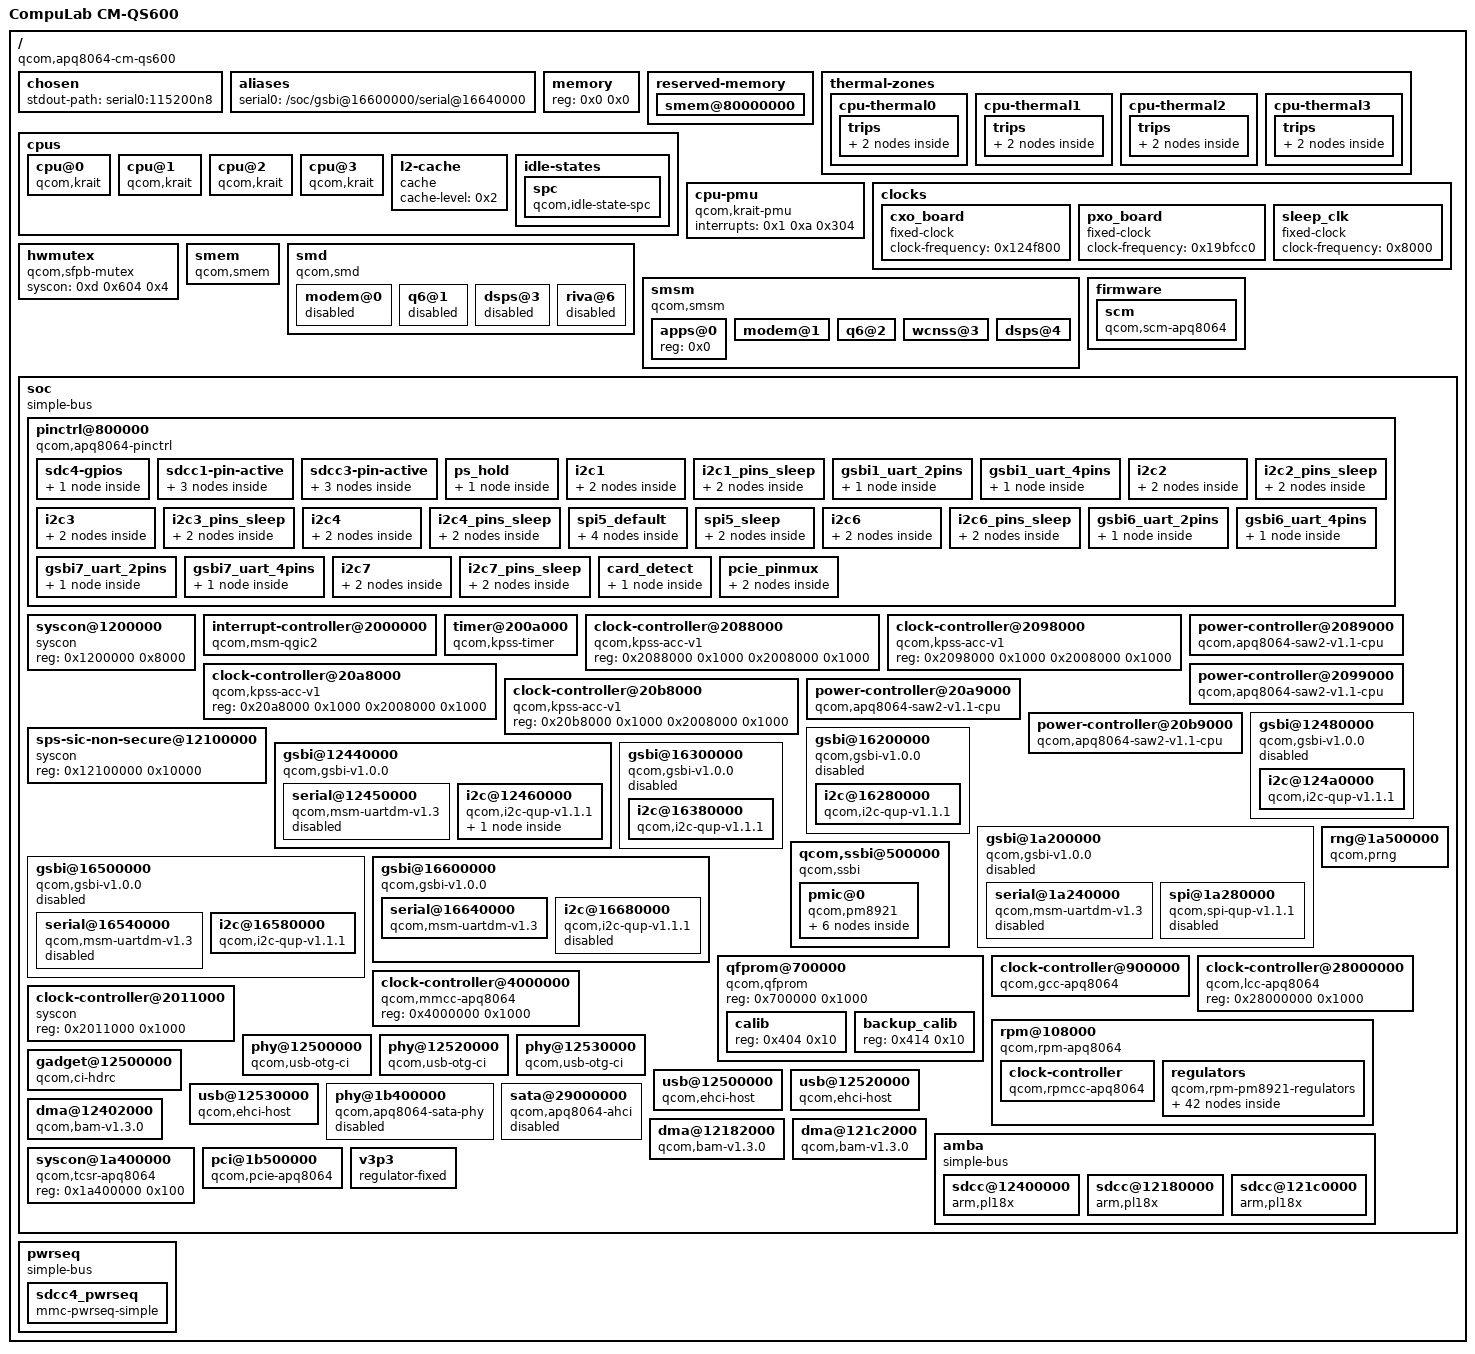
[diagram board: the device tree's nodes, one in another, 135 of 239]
/dts-v1/;

/ {
	#address-cells = <0x1>;
	#size-cells = <0x1>;
	model = "CompuLab CM-QS600";
	compatible = "qcom,apq8064-cm-qs600", "qcom,apq8064";
	interrupt-parent = <0x1>;

	chosen {
		stdout-path = "serial0:115200n8";
	};

	aliases {
		serial0 = "/soc/gsbi@16600000/serial@16640000";
	};

	memory {
		device_type = "memory";
		reg = <0x0 0x0>;
	};

	reserved-memory {
		#address-cells = <0x1>;
		#size-cells = <0x1>;
		ranges;

		smem@80000000 {
			reg = <0x80000000 0x200000>;
			no-map;
			phandle = <0xe>;
		};
	};

	cpus {
		#address-cells = <0x1>;
		#size-cells = <0x0>;

		cpu@0 {
			compatible = "qcom,krait";
			enable-method = "qcom,kpss-acc-v1";
			device_type = "cpu";
			reg = <0x0>;
			next-level-cache = <0x2>;
			qcom,acc = <0x3>;
			qcom,saw = <0x4>;
			cpu-idle-states = <0x5>;
		};

		cpu@1 {
			compatible = "qcom,krait";
			enable-method = "qcom,kpss-acc-v1";
			device_type = "cpu";
			reg = <0x1>;
			next-level-cache = <0x2>;
			qcom,acc = <0x6>;
			qcom,saw = <0x7>;
			cpu-idle-states = <0x5>;
		};

		cpu@2 {
			compatible = "qcom,krait";
			enable-method = "qcom,kpss-acc-v1";
			device_type = "cpu";
			reg = <0x2>;
			next-level-cache = <0x2>;
			qcom,acc = <0x8>;
			qcom,saw = <0x9>;
			cpu-idle-states = <0x5>;
		};

		cpu@3 {
			compatible = "qcom,krait";
			enable-method = "qcom,kpss-acc-v1";
			device_type = "cpu";
			reg = <0x3>;
			next-level-cache = <0x2>;
			qcom,acc = <0xa>;
			qcom,saw = <0xb>;
			cpu-idle-states = <0x5>;
		};

		l2-cache {
			compatible = "cache";
			cache-level = <0x2>;
			phandle = <0x2>;
		};

		idle-states {

			spc {
				compatible = "qcom,idle-state-spc", "arm,idle-state";
				entry-latency-us = <0x190>;
				exit-latency-us = <0x384>;
				min-residency-us = <0xbb8>;
				phandle = <0x5>;
			};
		};
	};

	thermal-zones {

		cpu-thermal0 {
			polling-delay-passive = <0xfa>;
			polling-delay = <0x3e8>;
			thermal-sensors = <0xc 0x7>;
			coefficients = <0x4af 0x0>;

			trips {

				trip0 {
					temperature = <0x124f8>;
					hysteresis = <0x7d0>;
					type = "passive";
					phandle = <0x3f>;
				};

				trip1 {
					temperature = <0x1adb0>;
					hysteresis = <0x7d0>;
					type = "critical";
					phandle = <0x40>;
				};
			};
		};

		cpu-thermal1 {
			polling-delay-passive = <0xfa>;
			polling-delay = <0x3e8>;
			thermal-sensors = <0xc 0x8>;
			coefficients = <0x46c 0x0>;

			trips {

				trip0 {
					temperature = <0x124f8>;
					hysteresis = <0x7d0>;
					type = "passive";
					phandle = <0x41>;
				};

				trip1 {
					temperature = <0x1adb0>;
					hysteresis = <0x7d0>;
					type = "critical";
					phandle = <0x42>;
				};
			};
		};

		cpu-thermal2 {
			polling-delay-passive = <0xfa>;
			polling-delay = <0x3e8>;
			thermal-sensors = <0xc 0x9>;
			coefficients = <0x4af 0x0>;

			trips {

				trip0 {
					temperature = <0x124f8>;
					hysteresis = <0x7d0>;
					type = "passive";
					phandle = <0x43>;
				};

				trip1 {
					temperature = <0x1adb0>;
					hysteresis = <0x7d0>;
					type = "critical";
					phandle = <0x44>;
				};
			};
		};

		cpu-thermal3 {
			polling-delay-passive = <0xfa>;
			polling-delay = <0x3e8>;
			thermal-sensors = <0xc 0xa>;
			coefficients = <0x46c 0x0>;

			trips {

				trip0 {
					temperature = <0x124f8>;
					hysteresis = <0x7d0>;
					type = "passive";
					phandle = <0x45>;
				};

				trip1 {
					temperature = <0x1adb0>;
					hysteresis = <0x7d0>;
					type = "critical";
					phandle = <0x46>;
				};
			};
		};
	};

	cpu-pmu {
		compatible = "qcom,krait-pmu";
		interrupts = <0x1 0xa 0x304>;
	};

	clocks {

		cxo_board {
			compatible = "fixed-clock";
			#clock-cells = <0x0>;
			clock-frequency = <0x124f800>;
		};

		pxo_board {
			compatible = "fixed-clock";
			#clock-cells = <0x0>;
			clock-frequency = <0x19bfcc0>;
		};

		sleep_clk {
			compatible = "fixed-clock";
			#clock-cells = <0x0>;
			clock-frequency = <0x8000>;
		};
	};

	hwmutex {
		compatible = "qcom,sfpb-mutex";
		syscon = <0xd 0x604 0x4>;
		#hwlock-cells = <0x1>;
		phandle = <0xf>;
	};

	smem {
		compatible = "qcom,smem";
		memory-region = <0xe>;
		hwlocks = <0xf 0x3>;
	};

	smd {
		compatible = "qcom,smd";

		modem@0 {
			interrupts = <0x0 0x25 0x1>;
			qcom,ipc = <0x10 0x8 0x3>;
			qcom,smd-edge = <0x0>;
			status = "disabled";
		};

		q6@1 {
			interrupts = <0x0 0x5a 0x1>;
			qcom,ipc = <0x10 0x8 0xf>;
			qcom,smd-edge = <0x1>;
			status = "disabled";
		};

		dsps@3 {
			interrupts = <0x0 0x8a 0x1>;
			qcom,ipc = <0x11 0x4080 0x0>;
			qcom,smd-edge = <0x3>;
			status = "disabled";
		};

		riva@6 {
			interrupts = <0x0 0xc6 0x1>;
			qcom,ipc = <0x10 0x8 0x19>;
			qcom,smd-edge = <0x6>;
			status = "disabled";
		};
	};

	smsm {
		compatible = "qcom,smsm";
		#address-cells = <0x1>;
		#size-cells = <0x0>;
		qcom,ipc-1 = <0x10 0x8 0x4>;
		qcom,ipc-2 = <0x10 0x8 0xe>;
		qcom,ipc-3 = <0x10 0x8 0x17>;
		qcom,ipc-4 = <0x11 0x4094 0x0>;

		apps@0 {
			reg = <0x0>;
			#qcom,smem-state-cells = <0x1>;
			phandle = <0x47>;
		};

		modem@1 {
			reg = <0x1>;
			interrupts = <0x0 0x26 0x1>;
			interrupt-controller;
			#interrupt-cells = <0x2>;
			phandle = <0x48>;
		};

		q6@2 {
			reg = <0x2>;
			interrupts = <0x0 0x59 0x1>;
			interrupt-controller;
			#interrupt-cells = <0x2>;
			phandle = <0x49>;
		};

		wcnss@3 {
			reg = <0x3>;
			interrupts = <0x0 0xcc 0x1>;
			interrupt-controller;
			#interrupt-cells = <0x2>;
			phandle = <0x4a>;
		};

		dsps@4 {
			reg = <0x4>;
			interrupts = <0x0 0x89 0x1>;
			interrupt-controller;
			#interrupt-cells = <0x2>;
			phandle = <0x4b>;
		};
	};

	firmware {

		scm {
			compatible = "qcom,scm-apq8064";
		};
	};

	soc {
		#address-cells = <0x1>;
		#size-cells = <0x1>;
		ranges;
		compatible = "simple-bus";
		phandle = <0x4c>;

		pinctrl@800000 {
			compatible = "qcom,apq8064-pinctrl";
			reg = <0x800000 0x4000>;
			gpio-controller;
			#gpio-cells = <0x2>;
			interrupt-controller;
			#interrupt-cells = <0x2>;
			interrupts = <0x0 0x10 0x4>;
			pinctrl-names = "default";
			pinctrl-0 = <0x12>;
			phandle = <0x23>;

			sdc4-gpios {
				phandle = <0x39>;

				pios {
					pins = "gpio63", "gpio64", "gpio65", "gpio66", "gpio67", "gpio68";
					function = "sdc4";
				};
			};

			sdcc1-pin-active {
				phandle = <0x32>;

				clk {
					pins = "sdc1_clk";
					drive-strengh = <0x10>;
					bias-disable;
				};

				cmd {
					pins = "sdc1_cmd";
					drive-strengh = <0xa>;
					bias-pull-up;
				};

				data {
					pins = "sdc1_data";
					drive-strengh = <0xa>;
					bias-pull-up;
				};
			};

			sdcc3-pin-active {
				phandle = <0x4d>;

				clk {
					pins = "sdc3_clk";
					drive-strengh = <0x8>;
					bias-disable;
				};

				cmd {
					pins = "sdc3_cmd";
					drive-strengh = <0x8>;
					bias-pull-up;
				};

				data {
					pins = "sdc3_data";
					drive-strengh = <0x8>;
					bias-pull-up;
				};
			};

			ps_hold {
				phandle = <0x12>;

				mux {
					pins = "gpio78";
					function = "ps_hold";
				};
			};

			i2c1 {
				phandle = <0x14>;

				mux {
					pins = "gpio20", "gpio21";
					function = "gsbi1";
				};

				pinconf {
					pins = "gpio20", "gpio21";
					drive-strength = <0x10>;
					bias-disable;
				};
			};

			i2c1_pins_sleep {
				phandle = <0x15>;

				mux {
					pins = "gpio20", "gpio21";
					function = "gpio";
				};

				pinconf {
					pins = "gpio20", "gpio21";
					drive-strength = <0x2>;
					bias-disable = <0x0>;
				};
			};

			gsbi1_uart_2pins {
				phandle = <0x4e>;

				mux {
					pins = "gpio18", "gpio19";
					function = "gsbi1";
				};
			};

			gsbi1_uart_4pins {
				phandle = <0x4f>;

				mux {
					pins = "gpio18", "gpio19", "gpio20", "gpio21";
					function = "gsbi1";
				};
			};

			i2c2 {
				phandle = <0x16>;

				mux {
					pins = "gpio24", "gpio25";
					function = "gsbi2";
				};

				pinconf {
					pins = "gpio24", "gpio25";
					drive-strength = <0x10>;
					bias-disable;
				};
			};

			i2c2_pins_sleep {
				phandle = <0x17>;

				mux {
					pins = "gpio24", "gpio25";
					function = "gpio";
				};

				pinconf {
					pins = "gpio24", "gpio25";
					drive-strength = <0x2>;
					bias-disable = <0x0>;
				};
			};

			i2c3 {
				phandle = <0x18>;

				mux {
					pins = "gpio8", "gpio9";
					function = "gsbi3";
				};

				pinconf {
					pins = "gpio8", "gpio9";
					drive-strength = <0x10>;
					bias-disable;
				};
			};

			i2c3_pins_sleep {
				phandle = <0x19>;

				mux {
					pins = "gpio8", "gpio9";
					function = "gpio";
				};

				pinconf {
					pins = "gpio8", "gpio9";
					drive-strength = <0x2>;
					bias-disable = <0x0>;
				};
			};

			i2c4 {
				phandle = <0x1a>;

				mux {
					pins = "gpio12", "gpio13";
					function = "gsbi4";
				};

				pinconf {
					pins = "gpio12", "gpio13";
					drive-strength = <0x10>;
					bias-disable;
				};
			};

			i2c4_pins_sleep {
				phandle = <0x1b>;

				mux {
					pins = "gpio12", "gpio13";
					function = "gpio";
				};

				pinconf {
					pins = "gpio12", "gpio13";
					drive-strength = <0x2>;
					bias-disable = <0x0>;
				};
			};

			spi5_default {
				phandle = <0x1c>;

				pinmux {
					pins = "gpio51", "gpio52", "gpio54";
					function = "gsbi5";
				};

				pinmux_cs {
					function = "gpio";
					pins = "gpio53";
				};

				pinconf {
					pins = "gpio51", "gpio52", "gpio54";
					drive-strength = <0x10>;
					bias-disable;
				};

				pinconf_cs {
					pins = "gpio53";
					drive-strength = <0x10>;
					bias-disable;
					output-high;
				};
			};

			spi5_sleep {
				phandle = <0x1d>;

				pinmux {
					function = "gpio";
					pins = "gpio51", "gpio52", "gpio53", "gpio54";
				};

				pinconf {
					pins = "gpio51", "gpio52", "gpio53", "gpio54";
					drive-strength = <0x2>;
					bias-pull-down;
				};
			};

			i2c6 {
				phandle = <0x1e>;

				mux {
					pins = "gpio16", "gpio17";
					function = "gsbi6";
				};

				pinconf {
					pins = "gpio16", "gpio17";
					drive-strength = <0x10>;
					bias-disable;
				};
			};

			i2c6_pins_sleep {
				phandle = <0x1f>;

				mux {
					pins = "gpio16", "gpio17";
					function = "gpio";
				};

				pinconf {
					pins = "gpio16", "gpio17";
					drive-strength = <0x2>;
					bias-disable = <0x0>;
				};
			};

			gsbi6_uart_2pins {
				phandle = <0x50>;

				mux {
					pins = "gpio14", "gpio15";
					function = "gsbi6";
				};
			};

			gsbi6_uart_4pins {
				phandle = <0x51>;

				mux {
					pins = "gpio14", "gpio15", "gpio16", "gpio17";
					function = "gsbi6";
				};
			};

			gsbi7_uart_2pins {
				phandle = <0x20>;

				mux {
					pins = "gpio82", "gpio83";
					function = "gsbi7";
				};
			};

			gsbi7_uart_4pins {
				phandle = <0x52>;

				mux {
					pins = "gpio82", "gpio83", "gpio84", "gpio85";
					function = "gsbi7";
				};
			};

			i2c7 {
				phandle = <0x21>;

				mux {
					pins = "gpio84", "gpio85";
					function = "gsbi7";
				};

				pinconf {
					pins = "gpio84", "gpio85";
					drive-strength = <0x10>;
					bias-disable;
				};
			};

			i2c7_pins_sleep {
				phandle = <0x22>;

				mux {
					pins = "gpio84", "gpio85";
					function = "gpio";
				};

				pinconf {
					pins = "gpio84", "gpio85";
					drive-strength = <0x2>;
					bias-disable = <0x0>;
				};
			};

			card_detect {
				phandle = <0x37>;

				mux {
					pins = "gpio26";
					function = "gpio";
					bias-disable;
				};
			};

			pcie_pinmux {
				phandle = <0x3c>;

				mux {
					pins = "gpio27";
					function = "gpio";
				};

				conf {
					pins = "gpio27";
					drive-strength = <0xc>;
					bias-disable;
				};
			};
		};

		syscon@1200000 {
			compatible = "syscon";
			reg = <0x1200000 0x8000>;
			phandle = <0xd>;
		};

		interrupt-controller@2000000 {
			compatible = "qcom,msm-qgic2";
			interrupt-controller;
			#interrupt-cells = <0x3>;
			reg = <0x2000000 0x1000 0x2002000 0x1000>;
			phandle = <0x1>;
		};

		timer@200a000 {
			compatible = "qcom,kpss-timer", "qcom,kpss-wdt-apq8064", "qcom,msm-timer";
			interrupts = <0x1 0x1 0x301 0x1 0x2 0x301 0x1 0x3 0x301>;
			reg = <0x200a000 0x100>;
			clock-frequency = <0x19bfcc0 0x8000>;
			cpu-offset = <0x80000>;
		};

		clock-controller@2088000 {
			compatible = "qcom,kpss-acc-v1";
			reg = <0x2088000 0x1000 0x2008000 0x1000>;
			phandle = <0x3>;
		};

		clock-controller@2098000 {
			compatible = "qcom,kpss-acc-v1";
			reg = <0x2098000 0x1000 0x2008000 0x1000>;
			phandle = <0x6>;
		};

		clock-controller@20a8000 {
			compatible = "qcom,kpss-acc-v1";
			reg = <0x20a8000 0x1000 0x2008000 0x1000>;
			phandle = <0x8>;
		};

		clock-controller@20b8000 {
			compatible = "qcom,kpss-acc-v1";
			reg = <0x20b8000 0x1000 0x2008000 0x1000>;
			phandle = <0xa>;
		};

		power-controller@2089000 {
			compatible = "qcom,apq8064-saw2-v1.1-cpu", "qcom,saw2";
			reg = <0x2089000 0x1000 0x2009000 0x1000>;
			regulator;
			phandle = <0x4>;
		};

		power-controller@2099000 {
			compatible = "qcom,apq8064-saw2-v1.1-cpu", "qcom,saw2";
			reg = <0x2099000 0x1000 0x2009000 0x1000>;
			regulator;
			phandle = <0x7>;
		};

		power-controller@20a9000 {
			compatible = "qcom,apq8064-saw2-v1.1-cpu", "qcom,saw2";
			reg = <0x20a9000 0x1000 0x2009000 0x1000>;
			regulator;
			phandle = <0x9>;
		};

		power-controller@20b9000 {
			compatible = "qcom,apq8064-saw2-v1.1-cpu", "qcom,saw2";
			reg = <0x20b9000 0x1000 0x2009000 0x1000>;
			regulator;
			phandle = <0xb>;
		};

		sps-sic-non-secure@12100000 {
			compatible = "syscon";
			reg = <0x12100000 0x10000>;
			phandle = <0x11>;
		};

		gsbi@12440000 {
			status = "okay";
			compatible = "qcom,gsbi-v1.0.0";
			cell-index = <0x1>;
			reg = <0x12440000 0x100>;
			clocks = <0xc 0x93>;
			clock-names = "iface";
			#address-cells = <0x1>;
			#size-cells = <0x1>;
			ranges;
			syscon-tcsr = <0x13>;
			qcom,mode = <0x2>;
			phandle = <0x53>;

			serial@12450000 {
				compatible = "qcom,msm-uartdm-v1.3", "qcom,msm-uartdm";
				reg = <0x12450000 0x100 0x12400000 0x3>;
				interrupts = <0x0 0xc1 0x0>;
				clocks = <0xc 0xa0 0xc 0x93>;
				clock-names = "core", "iface";
				status = "disabled";
				phandle = <0x54>;
			};

			i2c@12460000 {
				compatible = "qcom,i2c-qup-v1.1.1";
				pinctrl-0 = <0x14>;
				pinctrl-1 = <0x15>;
				pinctrl-names = "default", "sleep";
				reg = <0x12460000 0x1000>;
				interrupts = <0x0 0xc2 0x0>;
				clocks = <0xc 0xb8 0xc 0x93>;
				clock-names = "core", "iface";
				#address-cells = <0x1>;
				#size-cells = <0x0>;
				status = "okay";
				clock-frequency = <0x30d40>;
				phandle = <0x55>;

				eeprom@50 {
					compatible = "24c02";
					reg = <0x50>;
					pagesize = <0x20>;
				};
			};
		};

		gsbi@12480000 {
			status = "disabled";
			compatible = "qcom,gsbi-v1.0.0";
			cell-index = <0x2>;
			reg = <0x12480000 0x100>;
			clocks = <0xc 0x94>;
			clock-names = "iface";
			#address-cells = <0x1>;
			#size-cells = <0x1>;
			ranges;
			syscon-tcsr = <0x13>;
			phandle = <0x56>;

			i2c@124a0000 {
				compatible = "qcom,i2c-qup-v1.1.1";
				reg = <0x124a0000 0x1000>;
				pinctrl-0 = <0x16>;
				pinctrl-1 = <0x17>;
				pinctrl-names = "default", "sleep";
				interrupts = <0x0 0xc4 0x0>;
				clocks = <0xc 0xba 0xc 0x94>;
				clock-names = "core", "iface";
				#address-cells = <0x1>;
				#size-cells = <0x0>;
				phandle = <0x57>;
			};
		};

		gsbi@16200000 {
			status = "disabled";
			compatible = "qcom,gsbi-v1.0.0";
			cell-index = <0x3>;
			reg = <0x16200000 0x100>;
			clocks = <0xc 0x95>;
			clock-names = "iface";
			#address-cells = <0x1>;
			#size-cells = <0x1>;
			ranges;
			phandle = <0x58>;

			i2c@16280000 {
				compatible = "qcom,i2c-qup-v1.1.1";
				pinctrl-0 = <0x18>;
				pinctrl-1 = <0x19>;
				pinctrl-names = "default", "sleep";
				reg = <0x16280000 0x1000>;
				interrupts = <0x0 0x97 0x0>;
				clocks = <0xc 0xbc 0xc 0x95>;
				clock-names = "core", "iface";
				#address-cells = <0x1>;
				#size-cells = <0x0>;
				phandle = <0x59>;
			};
		};

		gsbi@16300000 {
			status = "disabled";
			compatible = "qcom,gsbi-v1.0.0";
			cell-index = <0x4>;
			reg = <0x16300000 0x3>;
			clocks = <0xc 0x96>;
			clock-names = "iface";
			#address-cells = <0x1>;
			#size-cells = <0x1>;
			ranges;
			phandle = <0x5a>;

			i2c@16380000 {
				compatible = "qcom,i2c-qup-v1.1.1";
				pinctrl-0 = <0x1a>;
				pinctrl-1 = <0x1b>;
				pinctrl-names = "default", "sleep";
				reg = <0x16380000 0x1000>;
				interrupts = <0x0 0x99 0x0>;
				clocks = <0xc 0xbe 0xc 0x96>;
				clock-names = "core", "iface";
				phandle = <0x5b>;
			};
		};

		gsbi@1a200000 {
			status = "disabled";
			compatible = "qcom,gsbi-v1.0.0";
			cell-index = <0x5>;
			reg = <0x1a200000 0x3>;
			clocks = <0xc 0x97>;
			clock-names = "iface";
			#address-cells = <0x1>;
			#size-cells = <0x1>;
			ranges;
			phandle = <0x5c>;

			serial@1a240000 {
				compatible = "qcom,msm-uartdm-v1.3", "qcom,msm-uartdm";
				reg = <0x1a240000 0x100 0x1a200000 0x3>;
				interrupts = <0x0 0x9a 0x0>;
				clocks = <0xc 0xa8 0xc 0x97>;
				clock-names = "core", "iface";
				status = "disabled";
				phandle = <0x5d>;
			};

			spi@1a280000 {
				compatible = "qcom,spi-qup-v1.1.1";
				reg = <0x1a280000 0x1000>;
				interrupts = <0x0 0x9b 0x0>;
				pinctrl-0 = <0x1c>;
				pinctrl-1 = <0x1d>;
				pinctrl-names = "default", "sleep";
				clocks = <0xc 0xc0 0xc 0x97>;
				clock-names = "core", "iface";
				status = "disabled";
				#address-cells = <0x1>;
				#size-cells = <0x0>;
				phandle = <0x5e>;
			};
		};

		gsbi@16500000 {
			status = "disabled";
			compatible = "qcom,gsbi-v1.0.0";
			cell-index = <0x6>;
			reg = <0x16500000 0x3>;
			clocks = <0xc 0x98>;
			clock-names = "iface";
			#address-cells = <0x1>;
			#size-cells = <0x1>;
			ranges;
			phandle = <0x5f>;

			serial@16540000 {
				compatible = "qcom,msm-uartdm-v1.3", "qcom,msm-uartdm";
				reg = <0x16540000 0x100 0x16500000 0x3>;
				interrupts = <0x0 0x9c 0x0>;
				clocks = <0xc 0xaa 0xc 0x98>;
				clock-names = "core", "iface";
				status = "disabled";
				phandle = <0x60>;
			};

			i2c@16580000 {
				compatible = "qcom,i2c-qup-v1.1.1";
				pinctrl-0 = <0x1e>;
				pinctrl-1 = <0x1f>;
				pinctrl-names = "default", "sleep";
				reg = <0x16580000 0x1000>;
				interrupts = <0x0 0x9d 0x0>;
				clocks = <0xc 0xc2 0xc 0x98>;
				clock-names = "core", "iface";
				phandle = <0x61>;
			};
		};

		gsbi@16600000 {
			status = "ok";
			compatible = "qcom,gsbi-v1.0.0";
			cell-index = <0x7>;
			reg = <0x16600000 0x100>;
			clocks = <0xc 0x99>;
			clock-names = "iface";
			#address-cells = <0x1>;
			#size-cells = <0x1>;
			ranges;
			syscon-tcsr = <0x13>;
			qcom,mode = <0x6>;
			phandle = <0x62>;

			serial@16640000 {
				compatible = "qcom,msm-uartdm-v1.3", "qcom,msm-uartdm";
				reg = <0x16640000 0x1000 0x16600000 0x1000>;
				interrupts = <0x0 0x9e 0x0>;
				clocks = <0xc 0xac 0xc 0x99>;
				clock-names = "core", "iface";
				status = "ok";
				pinctrl-names = "default";
				pinctrl-0 = <0x20>;
				phandle = <0x63>;
			};

			i2c@16680000 {
				compatible = "qcom,i2c-qup-v1.1.1";
				pinctrl-0 = <0x21>;
				pinctrl-1 = <0x22>;
				pinctrl-names = "default", "sleep";
				reg = <0x16680000 0x1000>;
				interrupts = <0x0 0x9f 0x0>;
				clocks = <0xc 0xc4 0xc 0x99>;
				clock-names = "core", "iface";
				status = "disabled";
				phandle = <0x64>;
			};
		};

		rng@1a500000 {
			compatible = "qcom,prng";
			reg = <0x1a500000 0x200>;
			clocks = <0xc 0x108>;
			clock-names = "core";
		};

		qcom,ssbi@500000 {
			compatible = "qcom,ssbi";
			reg = <0x500000 0x1000>;
			qcom,controller-type = "pmic-arbiter";

			pmic@0 {
				compatible = "qcom,pm8921";
				interrupt-parent = <0x23>;
				interrupts = <0x4a 0x8>;
				#interrupt-cells = <0x2>;
				interrupt-controller;
				#address-cells = <0x1>;
				#size-cells = <0x0>;
				phandle = <0x24>;

				gpio@150 {
					compatible = "qcom,pm8921-gpio", "qcom,ssbi-gpio";
					reg = <0x150>;
					interrupts = <0xc0 0x0 0xc1 0x0 0xc2 0x0 0xc3 0x0 0xc4 0x0 0xc5 0x0 0xc6 0x0 0xc7 0x0 0xc8 0x0 0xc9 0x0 0xca 0x0 0xcb 0x0 0xcc 0x0 0xcd 0x0 0xce 0x0 0xcf 0x0 0xd0 0x0 0xd1 0x0 0xd2 0x0 0xd3 0x0 0xd4 0x0 0xd5 0x0 0xd6 0x0 0xd7 0x0 0xd8 0x0 0xd9 0x0 0xda 0x0 0xdb 0x0 0xdc 0x0 0xdd 0x0 0xde 0x0 0xdf 0x0 0xe0 0x0 0xe1 0x0 0xe2 0x0 0xe3 0x0 0xe4 0x0 0xe5 0x0 0xe6 0x0 0xe7 0x0 0xe8 0x0 0xe9 0x0 0xea 0x0 0xeb 0x0>;
					gpio-controller;
					#gpio-cells = <0x2>;
					phandle = <0x3e>;

					wlan-gpios {
						phandle = <0x3d>;

						pios {
							pins = "gpio43";
							function = "normal";
							bias-disable;
							power-source = <0x2>;
						};
					};
				};

				mpps@50 {
					compatible = "qcom,pm8921-mpp", "qcom,ssbi-mpp";
					reg = <0x50>;
					gpio-controller;
					#gpio-cells = <0x2>;
					interrupts = <0x80 0x0 0x81 0x0 0x82 0x0 0x83 0x0 0x84 0x0 0x85 0x0 0x86 0x0 0x87 0x0 0x88 0x0 0x89 0x0 0x8a 0x0 0x8b 0x0>;
					phandle = <0x65>;
				};

				rtc@11d {
					compatible = "qcom,pm8921-rtc";
					interrupt-parent = <0x24>;
					interrupts = <0x27 0x1>;
					reg = <0x11d>;
					allow-set-time;
				};

				pwrkey@1c {
					compatible = "qcom,pm8921-pwrkey";
					reg = <0x1c>;
					interrupt-parent = <0x24>;
					interrupts = <0x32 0x1 0x33 0x1>;
					debounce = <0x3d09>;
					pull-up;
				};
			};
		};

		qfprom@700000 {
			compatible = "qcom,qfprom";
			reg = <0x700000 0x1000>;
			#address-cells = <0x1>;
			#size-cells = <0x1>;
			ranges;
			phandle = <0x66>;

			calib {
				reg = <0x404 0x10>;
				phandle = <0x25>;
			};

			backup_calib {
				reg = <0x414 0x10>;
				phandle = <0x26>;
			};
		};

		clock-controller@900000 {
			compatible = "qcom,gcc-apq8064";
			reg = <0x900000 0x4000>;
			nvmem-cells = <0x25 0x26>;
			nvmem-cell-names = "calib", "calib_backup";
			#clock-cells = <0x1>;
			#reset-cells = <0x1>;
			#thermal-sensor-cells = <0x1>;
			phandle = <0xc>;
		};

		clock-controller@28000000 {
			compatible = "qcom,lcc-apq8064";
			reg = <0x28000000 0x1000>;
			#clock-cells = <0x1>;
			#reset-cells = <0x1>;
			phandle = <0x67>;
		};

		clock-controller@4000000 {
			compatible = "qcom,mmcc-apq8064";
			reg = <0x4000000 0x1000>;
			#clock-cells = <0x1>;
			#reset-cells = <0x1>;
			phandle = <0x68>;
		};

		clock-controller@2011000 {
			compatible = "syscon";
			reg = <0x2011000 0x1000>;
			phandle = <0x10>;
		};

		rpm@108000 {
			compatible = "qcom,rpm-apq8064";
			reg = <0x108000 0x1000>;
			qcom,ipc = <0x10 0x8 0x2>;
			interrupts = <0x0 0x13 0x1 0x0 0x15 0x1 0x0 0x16 0x1>;
			interrupt-names = "ack", "err", "wakeup";

			clock-controller {
				compatible = "qcom,rpmcc-apq8064", "qcom,rpmcc";
				#clock-cells = <0x1>;
				phandle = <0x69>;
			};

			regulators {
				compatible = "qcom,rpm-pm8921-regulators";
				vin_lvs1_3_6-supply = <0x27>;
				vin_lvs2-supply = <0x28>;
				vin_lvs4_5_7-supply = <0x27>;
				vdd_l1_l2_l12_l18-supply = <0x27>;
				vdd_l24-supply = <0x28>;
				vdd_l25-supply = <0x28>;
				vdd_l26-supply = <0x29>;
				vdd_l27-supply = <0x29>;
				vdd_l28-supply = <0x29>;

				s1 {
					regulator-always-on;
					regulator-min-microvolt = <0x12b128>;
					regulator-max-microvolt = <0x12b128>;
					qcom,switch-mode-frequency = <0x30d400>;
					bias-pull-down;
					phandle = <0x28>;
				};

				s2 {
					phandle = <0x6a>;
				};

				s3 {
					regulator-min-microvolt = <0xf4240>;
					regulator-max-microvolt = <0x155cc0>;
					qcom,switch-mode-frequency = <0x493e00>;
					phandle = <0x2a>;
				};

				s4 {
					regulator-min-microvolt = <0x1b7740>;
					regulator-max-microvolt = <0x1b7740>;
					qcom,switch-mode-frequency = <0x30d400>;
					phandle = <0x27>;
				};

				s7 {
					regulator-min-microvolt = <0x13d620>;
					regulator-max-microvolt = <0x13d620>;
					qcom,switch-mode-frequency = <0x30d400>;
					phandle = <0x29>;
				};

				s8 {
					phandle = <0x6b>;
				};

				l1 {
					phandle = <0x6c>;
				};

				l2 {
					phandle = <0x6d>;
				};

				l3 {
					regulator-min-microvolt = <0x2e8a10>;
					regulator-max-microvolt = <0x325aa0>;
					bias-pull-down;
					phandle = <0x2b>;
				};

				l4 {
					regulator-min-microvolt = <0xf4240>;
					regulator-max-microvolt = <0x1b7740>;
					bias-pull-down;
					phandle = <0x2c>;
				};

				l5 {
					regulator-min-microvolt = <0x29f630>;
					regulator-max-microvolt = <0x2dc6c0>;
					bias-pull-down;
					phandle = <0x34>;
				};

				l6 {
					phandle = <0x6e>;
				};

				l7 {
					phandle = <0x6f>;
				};

				l8 {
					phandle = <0x70>;
				};

				l9 {
					phandle = <0x71>;
				};

				l10 {
					phandle = <0x72>;
				};

				l11 {
					phandle = <0x73>;
				};

				l12 {
					phandle = <0x74>;
				};

				l14 {
					phandle = <0x75>;
				};

				l15 {
					phandle = <0x76>;
				};

				l16 {
					phandle = <0x77>;
				};

				l17 {
					phandle = <0x78>;
				};

				l18 {
					phandle = <0x79>;
				};

				l21 {
					phandle = <0x7a>;
				};

				l22 {
					phandle = <0x7b>;
				};

				l23 {
					regulator-min-microvolt = <0x19f0a0>;
					regulator-max-microvolt = <0x1cfde0>;
					bias-pull-down;
					phandle = <0x2d>;
				};

				l24 {
					phandle = <0x7c>;
				};

				l25 {
					phandle = <0x7d>;
				};

				l26 {
					phandle = <0x7e>;
				};

				l27 {
					phandle = <0x7f>;
				};

				l28 {
					phandle = <0x80>;
				};

				l29 {
					phandle = <0x81>;
				};

				lvs1 {
					phandle = <0x82>;
				};

				lvs2 {
					phandle = <0x83>;
				};

				lvs3 {
					phandle = <0x84>;
				};

				lvs4 {
					phandle = <0x85>;
				};

				lvs5 {
					phandle = <0x86>;
				};

				lvs6 {
					bias-pull-down;
					phandle = <0x3b>;
				};

				lvs7 {
					phandle = <0x87>;
				};

				usb-switch {
					phandle = <0x88>;
				};

				hdmi-switch {
					bias-pull-down;
					phandle = <0x89>;
				};

				ncp {
					phandle = <0x8a>;
				};
			};
		};

		phy@12500000 {
			compatible = "qcom,usb-otg-ci";
			reg = <0x12500000 0x400>;
			interrupts = <0x0 0x64 0x0>;
			status = "okay";
			clocks = <0xc 0x80 0xc 0x7e>;
			clock-names = "core", "iface";
			resets = <0xc 0x40>;
			reset-names = "link";
			vddcx-supply = <0x2a>;
			v3p3-supply = <0x2b>;
			v1p8-supply = <0x2c>;
			phandle = <0x2e>;
		};

		phy@12520000 {
			compatible = "qcom,usb-otg-ci";
			reg = <0x12520000 0x400>;
			interrupts = <0x0 0xbc 0x0>;
			status = "okay";
			dr_mode = "host";
			clocks = <0xc 0x129 0xc 0x127>;
			clock-names = "core", "iface";
			resets = <0xc 0x64>;
			reset-names = "link";
			vddcx-supply = <0x2a>;
			v3p3-supply = <0x2b>;
			v1p8-supply = <0x2d>;
			phandle = <0x2f>;
		};

		phy@12530000 {
			compatible = "qcom,usb-otg-ci";
			reg = <0x12530000 0x400>;
			interrupts = <0x0 0xd7 0x0>;
			status = "okay";
			dr_mode = "host";
			clocks = <0xc 0x12c 0xc 0x12a>;
			clock-names = "core", "iface";
			resets = <0xc 0x65>;
			reset-names = "link";
			vddcx-supply = <0x2a>;
			v3p3-supply = <0x2b>;
			v1p8-supply = <0x2d>;
			phandle = <0x30>;
		};

		gadget@12500000 {
			compatible = "qcom,ci-hdrc";
			reg = <0x12500000 0x400>;
			status = "ok";
			dr_mode = "peripheral";
			interrupts = <0x0 0x64 0x0>;
			usb-phy = <0x2e>;
			phandle = <0x8b>;
		};

		usb@12500000 {
			compatible = "qcom,ehci-host";
			reg = <0x12500000 0x400>;
			interrupts = <0x0 0x64 0x0>;
			status = "ok";
			usb-phy = <0x2e>;
			phandle = <0x8c>;
		};

		usb@12520000 {
			compatible = "qcom,ehci-host";
			reg = <0x12520000 0x400>;
			interrupts = <0x0 0xbc 0x0>;
			status = "okay";
			usb-phy = <0x2f>;
			phandle = <0x8d>;
		};

		usb@12530000 {
			compatible = "qcom,ehci-host";
			reg = <0x12530000 0x400>;
			interrupts = <0x0 0xd7 0x0>;
			status = "okay";
			usb-phy = <0x30>;
			phandle = <0x8e>;
		};

		phy@1b400000 {
			compatible = "qcom,apq8064-sata-phy";
			status = "disabled";
			reg = <0x1b400000 0x200>;
			reg-names = "phy_mem";
			clocks = <0xc 0x12d>;
			clock-names = "cfg";
			#phy-cells = <0x0>;
			phandle = <0x31>;
		};

		sata@29000000 {
			compatible = "qcom,apq8064-ahci", "generic-ahci";
			status = "disabled";
			reg = <0x29000000 0x180>;
			interrupts = <0x0 0xd1 0x0>;
			clocks = <0xc 0x3b 0xc 0xed 0xc 0x12e 0xc 0xef 0xc 0xf0>;
			clock-names = "slave_iface", "iface", "bus", "rxoob", "core_pmalive";
			assigned-clocks = <0xc 0xef 0xc 0xf0>;
			assigned-clock-rates = <0x5f5e100 0x5f5e100>;
			phys = <0x31>;
			phy-names = "sata-phy";
			ports-implemented = <0x1>;
			phandle = <0x8f>;
		};

		dma@12402000 {
			compatible = "qcom,bam-v1.3.0";
			reg = <0x12402000 0x8000>;
			interrupts = <0x0 0x62 0x0>;
			clocks = <0xc 0x6e>;
			clock-names = "bam_clk";
			#dma-cells = <0x1>;
			qcom,ee = <0x0>;
			phandle = <0x33>;
		};

		dma@12182000 {
			compatible = "qcom,bam-v1.3.0";
			reg = <0x12182000 0x8000>;
			interrupts = <0x0 0x60 0x0>;
			clocks = <0xc 0x70>;
			clock-names = "bam_clk";
			#dma-cells = <0x1>;
			qcom,ee = <0x0>;
			phandle = <0x35>;
		};

		dma@121c2000 {
			compatible = "qcom,bam-v1.3.0";
			reg = <0x121c2000 0x8000>;
			interrupts = <0x0 0x5f 0x0>;
			clocks = <0xc 0x71>;
			clock-names = "bam_clk";
			#dma-cells = <0x1>;
			qcom,ee = <0x0>;
			phandle = <0x38>;
		};

		amba {
			compatible = "simple-bus";
			#address-cells = <0x1>;
			#size-cells = <0x1>;
			ranges;

			sdcc@12400000 {
				status = "okay";
				compatible = "arm,pl18x", "arm,primecell";
				pinctrl-names = "default";
				pinctrl-0 = <0x32>;
				arm,primecell-periphid = <0x51180>;
				reg = <0x12400000 0x2000>;
				interrupts = <0x0 0x68 0x4>;
				interrupt-names = "cmd_irq";
				clocks = <0xc 0x78 0xc 0x6e>;
				clock-names = "mclk", "apb_pclk";
				bus-width = <0x8>;
				max-frequency = <0x5b8d800>;
				non-removable;
				cap-sd-highspeed;
				cap-mmc-highspeed;
				dmas = <0x33 0x2 0x33 0x1>;
				dma-names = "tx", "rx";
				vmmc-supply = <0x34>;
				vqmmc-supply = <0x27>;
				phandle = <0x90>;
			};

			sdcc@12180000 {
				compatible = "arm,pl18x", "arm,primecell";
				arm,primecell-periphid = <0x51180>;
				status = "okay";
				reg = <0x12180000 0x2000>;
				interrupts = <0x0 0x66 0x4>;
				interrupt-names = "cmd_irq";
				clocks = <0xc 0x7a 0xc 0x70>;
				clock-names = "mclk", "apb_pclk";
				bus-width = <0x4>;
				cap-sd-highspeed;
				cap-mmc-highspeed;
				max-frequency = <0xb71b000>;
				no-1-8-v;
				dmas = <0x35 0x2 0x35 0x1>;
				dma-names = "tx", "rx";
				vmmc-supply = <0x36>;
				pinctrl-names = "default";
				pinctrl-0 = <0x37>;
				cd-gpios = <0x23 0x1a 0x1>;
				phandle = <0x91>;
			};

			sdcc@121c0000 {
				compatible = "arm,pl18x", "arm,primecell";
				arm,primecell-periphid = <0x51180>;
				status = "okay";
				reg = <0x121c0000 0x2000>;
				interrupts = <0x0 0x65 0x4>;
				interrupt-names = "cmd_irq";
				clocks = <0xc 0x7b 0xc 0x71>;
				clock-names = "mclk", "apb_pclk";
				bus-width = <0x4>;
				cap-sd-highspeed;
				cap-mmc-highspeed;
				max-frequency = <0x2dc6c00>;
				dmas = <0x38 0x2 0x38 0x1>;
				dma-names = "tx", "rx";
				pinctrl-names = "default";
				pinctrl-0 = <0x39>;
				vmmc-supply = <0x36>;
				vqmmc-supply = <0x36>;
				mmc-pwrseq = <0x3a>;
				phandle = <0x92>;
			};
		};

		syscon@1a400000 {
			compatible = "qcom,tcsr-apq8064", "syscon";
			reg = <0x1a400000 0x100>;
			phandle = <0x13>;
		};

		pci@1b500000 {
			compatible = "qcom,pcie-apq8064", "snps,dw-pcie";
			reg = <0x1b500000 0x1000 0x1b502000 0x80 0x1b600000 0x100 0xff00000 0x100000>;
			reg-names = "dbi", "elbi", "parf", "config";
			device_type = "pci";
			linux,pci-domain = <0x0>;
			bus-range = <0x0 0xff>;
			num-lanes = <0x1>;
			#address-cells = <0x3>;
			#size-cells = <0x2>;
			ranges = <0x81000000 0x0 0x0 0xfe00000 0x0 0x100000 0x82000000 0x0 0x0 0x8000000 0x0 0x7e00000>;
			interrupts = <0x0 0xee 0x0>;
			interrupt-names = "msi";
			#interrupt-cells = <0x1>;
			interrupt-map-mask = <0x0 0x0 0x0 0x7>;
			interrupt-map = <0x0 0x0 0x0 0x1 0x1 0x0 0x24 0x4 0x0 0x0 0x0 0x2 0x1 0x0 0x25 0x4 0x0 0x0 0x0 0x3 0x1 0x0 0x26 0x4 0x0 0x0 0x0 0x4 0x1 0x0 0x27 0x4>;
			clocks = <0xc 0x2b 0xc 0x2e 0xc 0x2d>;
			clock-names = "core", "iface", "phy";
			resets = <0xc 0x6c 0xc 0x6b 0xc 0x6a 0xc 0x69 0xc 0x68>;
			reset-names = "axi", "ahb", "por", "pci", "phy";
			status = "ok";
			vdda-supply = <0x2a>;
			vdda_phy-supply = <0x3b>;
			vdda_refclk-supply = <0x36>;
			pinctrl-0 = <0x3c>;
			pinctrl-names = "default";
			perst-gpio = <0x23 0x1b 0x1>;
			phandle = <0x93>;
		};

		v3p3 {
			compatible = "regulator-fixed";
			regulator-name = "PCIE V3P3";
			regulator-min-microvolt = <0x325aa0>;
			regulator-max-microvolt = <0x325aa0>;
			regulator-always-on;
			phandle = <0x36>;
		};
	};

	pwrseq {
		#address-cells = <0x1>;
		#size-cells = <0x1>;
		ranges;
		compatible = "simple-bus";

		sdcc4_pwrseq {
			pinctrl-names = "default";
			pinctrl-0 = <0x3d>;
			compatible = "mmc-pwrseq-simple";
			reset-gpios = <0x3e 0x2b 0x1>;
			phandle = <0x3a>;
		};
	};

	__symbols__ {
		smem_region = "/reserved-memory/smem@80000000";
		L2 = "/cpus/l2-cache";
		CPU_SPC = "/cpus/idle-states/spc";
		cpu_alert0 = "/thermal-zones/cpu-thermal0/trips/trip0";
		cpu_crit0 = "/thermal-zones/cpu-thermal0/trips/trip1";
		cpu_alert1 = "/thermal-zones/cpu-thermal1/trips/trip0";
		cpu_crit1 = "/thermal-zones/cpu-thermal1/trips/trip1";
		cpu_alert2 = "/thermal-zones/cpu-thermal2/trips/trip0";
		cpu_crit2 = "/thermal-zones/cpu-thermal2/trips/trip1";
		cpu_alert3 = "/thermal-zones/cpu-thermal3/trips/trip0";
		cpu_crit3 = "/thermal-zones/cpu-thermal3/trips/trip1";
		sfpb_mutex = "/hwmutex";
		apps_smsm = "/smsm/apps@0";
		modem_smsm = "/smsm/modem@1";
		q6_smsm = "/smsm/q6@2";
		wcnss_smsm = "/smsm/wcnss@3";
		dsps_smsm = "/smsm/dsps@4";
		soc = "/soc";
		tlmm_pinmux = "/soc/pinctrl@800000";
		sdc4_gpios = "/soc/pinctrl@800000/sdc4-gpios";
		sdcc1_pins = "/soc/pinctrl@800000/sdcc1-pin-active";
		sdcc3_pins = "/soc/pinctrl@800000/sdcc3-pin-active";
		ps_hold = "/soc/pinctrl@800000/ps_hold";
		i2c1_pins = "/soc/pinctrl@800000/i2c1";
		i2c1_pins_sleep = "/soc/pinctrl@800000/i2c1_pins_sleep";
		gsbi1_uart_2pins = "/soc/pinctrl@800000/gsbi1_uart_2pins";
		gsbi1_uart_4pins = "/soc/pinctrl@800000/gsbi1_uart_4pins";
		i2c2_pins = "/soc/pinctrl@800000/i2c2";
		i2c2_pins_sleep = "/soc/pinctrl@800000/i2c2_pins_sleep";
		i2c3_pins = "/soc/pinctrl@800000/i2c3";
		i2c3_pins_sleep = "/soc/pinctrl@800000/i2c3_pins_sleep";
		i2c4_pins = "/soc/pinctrl@800000/i2c4";
		i2c4_pins_sleep = "/soc/pinctrl@800000/i2c4_pins_sleep";
		spi5_default = "/soc/pinctrl@800000/spi5_default";
		spi5_sleep = "/soc/pinctrl@800000/spi5_sleep";
		i2c6_pins = "/soc/pinctrl@800000/i2c6";
		i2c6_pins_sleep = "/soc/pinctrl@800000/i2c6_pins_sleep";
		gsbi6_uart_2pins = "/soc/pinctrl@800000/gsbi6_uart_2pins";
		gsbi6_uart_4pins = "/soc/pinctrl@800000/gsbi6_uart_4pins";
		gsbi7_uart_2pins = "/soc/pinctrl@800000/gsbi7_uart_2pins";
		gsbi7_uart_4pins = "/soc/pinctrl@800000/gsbi7_uart_4pins";
		i2c7_pins = "/soc/pinctrl@800000/i2c7";
		i2c7_pins_sleep = "/soc/pinctrl@800000/i2c7_pins_sleep";
		card_detect = "/soc/pinctrl@800000/card_detect";
		pcie_pins = "/soc/pinctrl@800000/pcie_pinmux";
		sfpb_wrapper_mutex = "/soc/syscon@1200000";
		intc = "/soc/interrupt-controller@2000000";
		acc0 = "/soc/clock-controller@2088000";
		acc1 = "/soc/clock-controller@2098000";
		acc2 = "/soc/clock-controller@20a8000";
		acc3 = "/soc/clock-controller@20b8000";
		saw0 = "/soc/power-controller@2089000";
		saw1 = "/soc/power-controller@2099000";
		saw2 = "/soc/power-controller@20a9000";
		saw3 = "/soc/power-controller@20b9000";
		sps_sic_non_secure = "/soc/sps-sic-non-secure@12100000";
		gsbi1 = "/soc/gsbi@12440000";
		gsbi1_serial = "/soc/gsbi@12440000/serial@12450000";
		gsbi1_i2c = "/soc/gsbi@12440000/i2c@12460000";
		gsbi2 = "/soc/gsbi@12480000";
		gsbi2_i2c = "/soc/gsbi@12480000/i2c@124a0000";
		gsbi3 = "/soc/gsbi@16200000";
		gsbi3_i2c = "/soc/gsbi@16200000/i2c@16280000";
		gsbi4 = "/soc/gsbi@16300000";
		gsbi4_i2c = "/soc/gsbi@16300000/i2c@16380000";
		gsbi5 = "/soc/gsbi@1a200000";
		gsbi5_serial = "/soc/gsbi@1a200000/serial@1a240000";
		gsbi5_spi = "/soc/gsbi@1a200000/spi@1a280000";
		gsbi6 = "/soc/gsbi@16500000";
		gsbi6_serial = "/soc/gsbi@16500000/serial@16540000";
		gsbi6_i2c = "/soc/gsbi@16500000/i2c@16580000";
		gsbi7 = "/soc/gsbi@16600000";
		gsbi7_serial = "/soc/gsbi@16600000/serial@16640000";
		gsbi7_i2c = "/soc/gsbi@16600000/i2c@16680000";
		pmicintc = "/soc/qcom,ssbi@500000/pmic@0";
		pm8921_gpio = "/soc/qcom,ssbi@500000/pmic@0/gpio@150";
		wlan_default_gpios = "/soc/qcom,ssbi@500000/pmic@0/gpio@150/wlan-gpios";
		pm8921_mpps = "/soc/qcom,ssbi@500000/pmic@0/mpps@50";
		qfprom = "/soc/qfprom@700000";
		tsens_calib = "/soc/qfprom@700000/calib";
		tsens_backup = "/soc/qfprom@700000/backup_calib";
		gcc = "/soc/clock-controller@900000";
		lcc = "/soc/clock-controller@28000000";
		mmcc = "/soc/clock-controller@4000000";
		l2cc = "/soc/clock-controller@2011000";
		rpmcc = "/soc/rpm@108000/clock-controller";
		pm8921_s1 = "/soc/rpm@108000/regulators/s1";
		pm8921_s2 = "/soc/rpm@108000/regulators/s2";
		pm8921_s3 = "/soc/rpm@108000/regulators/s3";
		pm8921_s4 = "/soc/rpm@108000/regulators/s4";
		pm8921_s7 = "/soc/rpm@108000/regulators/s7";
		pm8921_s8 = "/soc/rpm@108000/regulators/s8";
		pm8921_l1 = "/soc/rpm@108000/regulators/l1";
		pm8921_l2 = "/soc/rpm@108000/regulators/l2";
		pm8921_l3 = "/soc/rpm@108000/regulators/l3";
		pm8921_l4 = "/soc/rpm@108000/regulators/l4";
		pm8921_l5 = "/soc/rpm@108000/regulators/l5";
		pm8921_l6 = "/soc/rpm@108000/regulators/l6";
		pm8921_l7 = "/soc/rpm@108000/regulators/l7";
		pm8921_l8 = "/soc/rpm@108000/regulators/l8";
		pm8921_l9 = "/soc/rpm@108000/regulators/l9";
		pm8921_l10 = "/soc/rpm@108000/regulators/l10";
		pm8921_l11 = "/soc/rpm@108000/regulators/l11";
		pm8921_l12 = "/soc/rpm@108000/regulators/l12";
		pm8921_l14 = "/soc/rpm@108000/regulators/l14";
		pm8921_l15 = "/soc/rpm@108000/regulators/l15";
		pm8921_l16 = "/soc/rpm@108000/regulators/l16";
		pm8921_l17 = "/soc/rpm@108000/regulators/l17";
		pm8921_l18 = "/soc/rpm@108000/regulators/l18";
		pm8921_l21 = "/soc/rpm@108000/regulators/l21";
		pm8921_l22 = "/soc/rpm@108000/regulators/l22";
		pm8921_l23 = "/soc/rpm@108000/regulators/l23";
		pm8921_l24 = "/soc/rpm@108000/regulators/l24";
		pm8921_l25 = "/soc/rpm@108000/regulators/l25";
		pm8921_l26 = "/soc/rpm@108000/regulators/l26";
		pm8921_l27 = "/soc/rpm@108000/regulators/l27";
		pm8921_l28 = "/soc/rpm@108000/regulators/l28";
		pm8921_l29 = "/soc/rpm@108000/regulators/l29";
		pm8921_lvs1 = "/soc/rpm@108000/regulators/lvs1";
		pm8921_lvs2 = "/soc/rpm@108000/regulators/lvs2";
		pm8921_lvs3 = "/soc/rpm@108000/regulators/lvs3";
		pm8921_lvs4 = "/soc/rpm@108000/regulators/lvs4";
		pm8921_lvs5 = "/soc/rpm@108000/regulators/lvs5";
		pm8921_lvs6 = "/soc/rpm@108000/regulators/lvs6";
		pm8921_lvs7 = "/soc/rpm@108000/regulators/lvs7";
		pm8921_usb_switch = "/soc/rpm@108000/regulators/usb-switch";
		pm8921_hdmi_switch = "/soc/rpm@108000/regulators/hdmi-switch";
		pm8921_ncp = "/soc/rpm@108000/regulators/ncp";
		usb1_phy = "/soc/phy@12500000";
		usb3_phy = "/soc/phy@12520000";
		usb4_phy = "/soc/phy@12530000";
		gadget1 = "/soc/gadget@12500000";
		usb1 = "/soc/usb@12500000";
		usb3 = "/soc/usb@12520000";
		usb4 = "/soc/usb@12530000";
		sata_phy0 = "/soc/phy@1b400000";
		sata0 = "/soc/sata@29000000";
		sdcc1bam = "/soc/dma@12402000";
		sdcc3bam = "/soc/dma@12182000";
		sdcc4bam = "/soc/dma@121c2000";
		sdcc1 = "/soc/amba/sdcc@12400000";
		sdcc3 = "/soc/amba/sdcc@12180000";
		sdcc4 = "/soc/amba/sdcc@121c0000";
		tcsr = "/soc/syscon@1a400000";
		pcie = "/soc/pci@1b500000";
		v3p3_fixed = "/soc/v3p3";
		sdcc4_pwrseq = "/pwrseq/sdcc4_pwrseq";
	};
};
